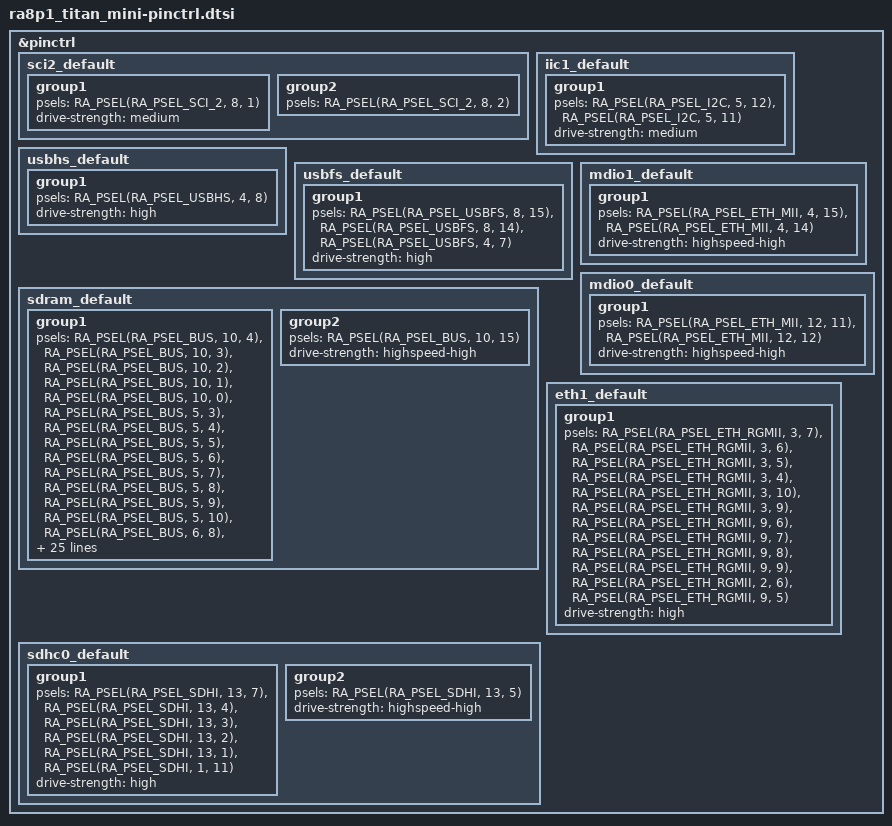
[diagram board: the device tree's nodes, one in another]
/*
 * SPDX-FileCopyrightText: Copyright The Zephyr Project Contributors
 * SPDX-License-Identifier: Apache-2.0
 */

&pinctrl {
	sci2_default: sci2_default {
		group1 {
			/* tx */
			psels = <RA_PSEL(RA_PSEL_SCI_2, 8, 1)>;
			drive-strength = "medium";
		};

		group2 {
			/* rx */
			psels = <RA_PSEL(RA_PSEL_SCI_2, 8, 2)>;
		};
	};

	iic1_default: iic1_default {
		group1 {
			/* SCL1 SDA1*/
			psels = <RA_PSEL(RA_PSEL_I2C, 5, 12)>,
				<RA_PSEL(RA_PSEL_I2C, 5, 11)>;
			drive-strength = "medium";
		};
	};

	usbhs_default: usbhs_default {
		group1 {
			psels = <RA_PSEL(RA_PSEL_USBHS, 4, 8)>; /* VBUS */
			drive-strength = "high";
		};
	};

	usbfs_default: usbfs_default {
		group1 {
			psels = <RA_PSEL(RA_PSEL_USBFS, 8, 15)>, /* USB_DM */
				<RA_PSEL(RA_PSEL_USBFS, 8, 14)>, /* USB_DP */
				<RA_PSEL(RA_PSEL_USBFS, 4, 7)>;	 /* VBUS */
			drive-strength = "high";
		};
	};

	sdram_default: sdram_default {
		group1 {
			psels = <RA_PSEL(RA_PSEL_BUS, 10, 4)>, /* SDRAM_A1 */
				<RA_PSEL(RA_PSEL_BUS, 10, 3)>, /* SDRAM_A2 */
				<RA_PSEL(RA_PSEL_BUS, 10, 2)>, /* SDRAM_A3 */
				<RA_PSEL(RA_PSEL_BUS, 10, 1)>, /* SDRAM_A4 */
				<RA_PSEL(RA_PSEL_BUS, 10, 0)>, /* SDRAM_A5 */
				<RA_PSEL(RA_PSEL_BUS, 5, 3)>, /* SDRAM_A6 */
				<RA_PSEL(RA_PSEL_BUS, 5, 4)>, /* SDRAM_A7 */
				<RA_PSEL(RA_PSEL_BUS, 5, 5)>, /* SDRAM_A8 */
				<RA_PSEL(RA_PSEL_BUS, 5, 6)>, /* SDRAM_A9 */
				<RA_PSEL(RA_PSEL_BUS, 5, 7)>, /* SDRAM_A10 */
				<RA_PSEL(RA_PSEL_BUS, 5, 8)>, /* SDRAM_A11 */
				<RA_PSEL(RA_PSEL_BUS, 5, 9)>, /* SDRAM_A12 */
				<RA_PSEL(RA_PSEL_BUS, 5, 10)>, /* SDRAM_A13 */
				<RA_PSEL(RA_PSEL_BUS, 6, 8)>, /* SDRAM_A14 */
				<RA_PSEL(RA_PSEL_BUS, 13, 0)>, /* SDRAM_A15 */
				<RA_PSEL(RA_PSEL_BUS, 3, 2)>, /* SDRAM_DQ0 */
				<RA_PSEL(RA_PSEL_BUS, 3, 1)>, /* SDRAM_DQ1 */
				<RA_PSEL(RA_PSEL_BUS, 3, 0)>, /* SDRAM_DQ2 */
				<RA_PSEL(RA_PSEL_BUS, 1, 12)>, /* SDRAM_DQ3 */
				<RA_PSEL(RA_PSEL_BUS, 1, 13)>, /* SDRAM_DQ4 */
				<RA_PSEL(RA_PSEL_BUS, 1, 14)>, /* SDRAM_DQ5 */
				<RA_PSEL(RA_PSEL_BUS, 1, 15)>, /* SDRAM_DQ6 */
				<RA_PSEL(RA_PSEL_BUS, 6, 9)>, /* SDRAM_DQ7 */
				<RA_PSEL(RA_PSEL_BUS, 10, 11)>, /* SDRAM_DQ8 */
				<RA_PSEL(RA_PSEL_BUS, 10, 12)>, /* SDRAM_DQ9 */
				<RA_PSEL(RA_PSEL_BUS, 10, 13)>, /* SDRAM_DQ10 */
				<RA_PSEL(RA_PSEL_BUS, 10, 14)>, /* SDRAM_DQ11 */
				<RA_PSEL(RA_PSEL_BUS, 6, 10)>, /* SDRAM_DQ12 */
				<RA_PSEL(RA_PSEL_BUS, 6, 11)>, /* SDRAM_DQ13 */
				<RA_PSEL(RA_PSEL_BUS, 6, 12)>, /* SDRAM_DQ14 */
				<RA_PSEL(RA_PSEL_BUS, 6, 13)>, /* SDRAM_DQ15 */
				<RA_PSEL(RA_PSEL_BUS, 6, 14)>, /* SDRAM_DQM0 */
				<RA_PSEL(RA_PSEL_BUS, 10, 5)>, /* SDRAM_DQM1 */
				<RA_PSEL(RA_PSEL_BUS, 10, 8)>, /* SDRAM_WE */
				<RA_PSEL(RA_PSEL_BUS, 10, 9)>, /* SDRAM_CAS */
				<RA_PSEL(RA_PSEL_BUS, 10, 10)>, /* SDRAM_RAS */
				<RA_PSEL(RA_PSEL_BUS, 8, 13)>, /* SDRAM_CS */
				<RA_PSEL(RA_PSEL_BUS, 10, 6)>; /* SDRAM_CKE */
			drive-strength = "high";
		};

		group2 {
			psels = <RA_PSEL(RA_PSEL_BUS, 10, 15)>; /* SDRAM_SDCLK */
			drive-strength = "highspeed-high";
		};
	};

	mdio1_default: mdio1_default {
		group1 {
			psels = <RA_PSEL(RA_PSEL_ETH_MII, 4, 15)>, /* MDC */
				<RA_PSEL(RA_PSEL_ETH_MII, 4, 14)>; /* MDIO */
			drive-strength = "highspeed-high";
		};
	};

	mdio0_default: mdio0_default {
		group1 {
			psels = <RA_PSEL(RA_PSEL_ETH_MII, 12, 11)>, /* MDC */
				<RA_PSEL(RA_PSEL_ETH_MII, 12, 12)>; /* MDIO */
			drive-strength = "highspeed-high";
		};
	};

	eth1_default: eth1_default {
		group1 {
			psels = <RA_PSEL(RA_PSEL_ETH_RGMII, 3, 7)>, /* RGMII_TXD0 */
				<RA_PSEL(RA_PSEL_ETH_RGMII, 3, 6)>, /* RGMII_TXD1 */
				<RA_PSEL(RA_PSEL_ETH_RGMII, 3, 5)>, /* RGMII_TXD2 */
				<RA_PSEL(RA_PSEL_ETH_RGMII, 3, 4)>, /* RGMII_TXD3 */
				<RA_PSEL(RA_PSEL_ETH_RGMII, 3, 10)>, /* RGMII_TX_CTL */
				<RA_PSEL(RA_PSEL_ETH_RGMII, 3, 9)>, /* RGMII_TX_CLK */
				<RA_PSEL(RA_PSEL_ETH_RGMII, 9, 6)>, /* RGMII_RXD0 */
				<RA_PSEL(RA_PSEL_ETH_RGMII, 9, 7)>, /* RGMII_RXD1 */
				<RA_PSEL(RA_PSEL_ETH_RGMII, 9, 8)>, /* RGMII_RXD2 */
				<RA_PSEL(RA_PSEL_ETH_RGMII, 9, 9)>, /* RGMII_RXD3 */
				<RA_PSEL(RA_PSEL_ETH_RGMII, 2, 6)>, /* RGMII_RX_CTL */
				<RA_PSEL(RA_PSEL_ETH_RGMII, 9, 5)>; /* RGMII_RX_CLK */
			drive-strength = "high";
		};
	};

	sdhc0_default: sdhc0_default {
		group1 {
			psels = <RA_PSEL(RA_PSEL_SDHI, 13, 7)>, /* SDCD */
				<RA_PSEL(RA_PSEL_SDHI, 13, 4)>, /* SDCMD */
				<RA_PSEL(RA_PSEL_SDHI, 13, 3)>, /* SDDATA0 */
				<RA_PSEL(RA_PSEL_SDHI, 13, 2)>, /* SDDATA1 */
				<RA_PSEL(RA_PSEL_SDHI, 13, 1)>, /* SDDATA2 */
				<RA_PSEL(RA_PSEL_SDHI, 1, 11)>; /* SDDATA3 */
			drive-strength = "high";
		};

		group2 {
			psels = <RA_PSEL(RA_PSEL_SDHI, 13, 5)>; /* SDCLK */
			drive-strength = "highspeed-high";
		};
	};
};
